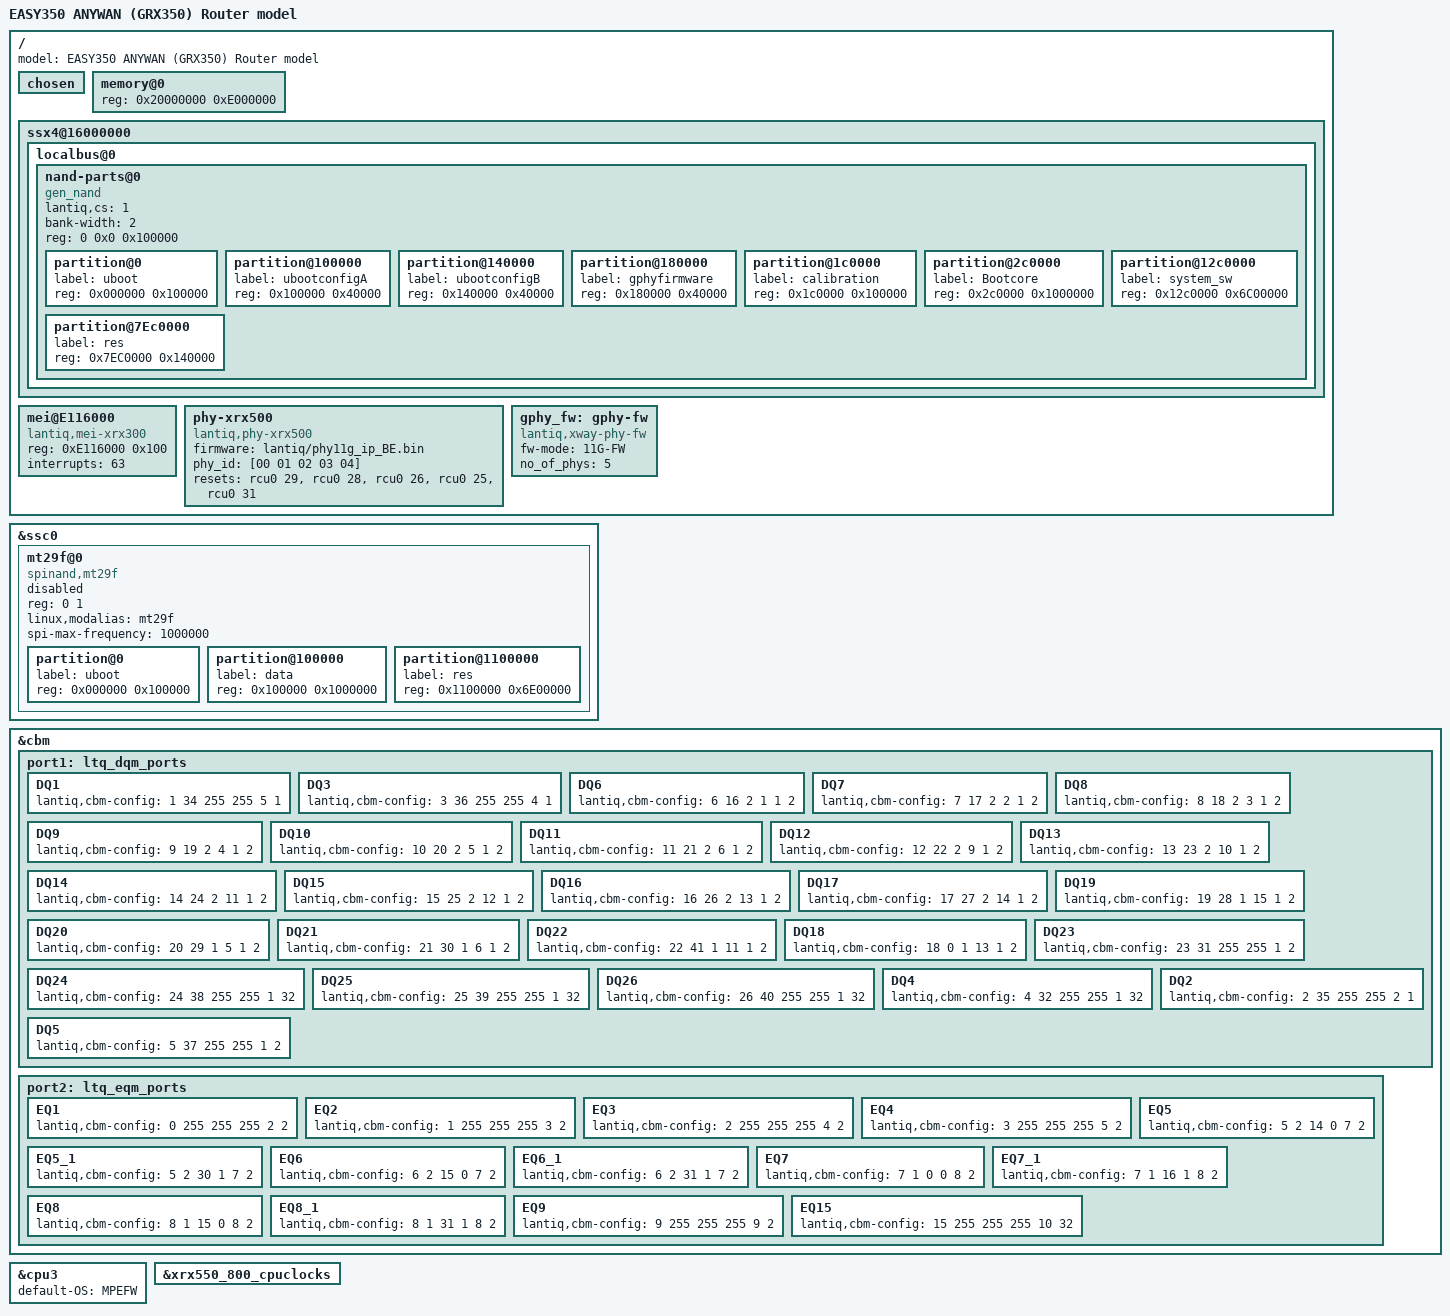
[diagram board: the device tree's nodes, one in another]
/dts-v1/;

/*****************************************************************
** Include a chip configuration file                             
*****************************************************************/
/include/ "xrx500.dtsi"
/*****************************************************************
** Include a board configuration file                             
*****************************************************************/
/include/ "xrx500_anywan_bc.dtsi"

/ {

	model = "EASY350 ANYWAN (GRX350) Router model";

	chosen {
		//bootargs-append = "maxcpus=4 cca=5 pci=pcie_bus_perf";
        };

	memory@0 {
		device_type = "memory";
		reg = <0x20000000 0xE000000>;
	};

	ssx4@16000000 {
			localbus@0 {
			ranges = <0 0 0x1c00000 0xfffff>;
			nand-parts@0 {
				compatible = "gen_nand","lantiq,nand-xway";
				lantiq,cs = <1>;
				bank-width = <2>;
				reg = <0 0x0 0x100000>;
				#address-cells = <1>;
				#size-cells = <1>;

                                partition@0 {
                                        label = "uboot";
                                        reg = <0x000000 0x100000>;
                                };

                                partition@100000 {
                                        label = "ubootconfigA";
                                        reg = <0x100000 0x40000>;
                                };

                                partition@140000 {
                                        label = "ubootconfigB";
                                        reg = <0x140000 0x40000>;
                                };

                                partition@180000 {
                                        label = "gphyfirmware";
                                        reg = <0x180000 0x40000>;
                                };

                                partition@1c0000 {
                                        label = "calibration";
                                        reg = <0x1c0000 0x100000>;
                                };

                               partition@2c0000 {
                                        label = "Bootcore";
                                        reg = <0x2c0000 0x1000000>;
                                };

                                partition@12c0000 {
                                        label = "system_sw";
                                        reg = <0x12c0000 0x6C00000>;
                                };

                                partition@7Ec0000 {
                                        label = "res";
                                        reg = <0x7EC0000 0x140000>;
                                };
			};
		};
	};
};

/******************************************************************************
** Model configuration: Enable SSC0 to support standard SPI devices (SPI Flash)  
******************************************************************************/
&ssc0 {
		
		mt29f@0 {
				status="disabled";
				#address-cells = <1>;
				#size-cells = <1>;
				reg = <0 1>;
				compatible = "spinand,mt29f";
				linux,modalias = "mt29f";
				spi-max-frequency = <1000000>;

				partition@0 {
					label = "uboot";
					reg = <0x000000 0x100000>;
				};

				partition@100000 {
					label = "data";
					reg = <0x100000 0x1000000>;
				};	
				
				partition@1100000 {
					label = "res";
					reg = <0x1100000 0x6E00000>;
				};
			};
};

/ {
/******************************************************************************
** Board configuration: MEI setting might not be needed for VRX318
******************************************************************************/
        mei@E116000 {
		            compatible = "lantiq,mei-xrx300";
					reg = <0xE116000 0x100>;
					interrupts = <63>;
	};
};

/{
/******************************************************************************
** Model configuration: Select Gigabit or fast ethernet firmware to load to 
** internel GPHY.
** GE mode : 11G-FW
** FE mode : 22F-FW
******************************************************************************/
	phy-xrx500 {
        compatible = "lantiq,phy-xrx500";
	    firmware = "lantiq/phy11g_ip_BE.bin";
		phy_id = [00 01 02 03 04];
		resets = <&rcu0 29>, <&rcu0 28>, <&rcu0 26>, <&rcu0 25>, <&rcu0 31>;
		reset-names = "phy0", "phy1", "phy2", "phy3", "phy4";
	};

	gphy_fw: gphy-fw {
		compatible = "lantiq,xway-phy-fw";
		fw-mode = "11G-FW"; /*"11G-FW"*/ /*22F-FW*/
		no_of_phys = <5>;
	};
};
/*******************************************************************************/

/******************************************************************************
** Model configuration: CBM sub-system feature configuration, the cbm node is 
** defined in Soc level. 
** <Port> <Queue> <DMA_Ctrl> <DMA_chnl> <EN/DIS/TYPE> <number of desc>
** <DIS 0> <EN 1> <TYPE DP_F_DEQ_CPU 0x2> <TYPE DP_F_DEQ_CPU1 0x3> 
** <TYPE DP_F_DEQ_MPE 0x4>
******************************************************************************/
&cbm {
			        status = "ok";
				port1: ltq_dqm_ports {
					DQ1 {
				 		lantiq,cbm-config = <1 34 255 255 5 1>;
					};
					DQ3 {
				 		lantiq,cbm-config = <3 36 255 255 4 1>;
					};
					DQ6 {
						lantiq,cbm-config = <6 16 2 1 1 2>;
					};
					DQ7 {
						lantiq,cbm-config = <7 17 2 2 1 2>;
					};
					DQ8 {
						lantiq,cbm-config = <8 18 2 3 1 2>;
					};
					DQ9 {
						lantiq,cbm-config = <9 19 2 4 1 2>;
					};
					DQ10 {
						lantiq,cbm-config = <10 20 2 5 1 2>;
					};
					DQ11 {
						lantiq,cbm-config = <11 21 2 6 1 2>;
					};
					DQ12 {
						lantiq,cbm-config = <12 22 2 9 1 2>;
					};
					DQ13 {
						lantiq,cbm-config = <13 23 2 10 1 2>;
					};
					DQ14 {
						lantiq,cbm-config = <14 24 2 11 1 2>;
					};
					DQ15 {
						lantiq,cbm-config = <15 25 2 12 1 2>;
					};
					DQ16 {
						lantiq,cbm-config = <16 26 2 13 1 2>;
					};
					DQ17 {
						lantiq,cbm-config = <17 27 2 14 1 2>;
					};
					DQ19 {
						lantiq,cbm-config = <19 28 1 15 1 2>;
					};
					DQ20 {
						lantiq,cbm-config = <20 29 1 5 1 2>;
					};
					DQ21 {
						lantiq,cbm-config = <21 30 1 6 1 2>;
					};
					DQ22 {
						lantiq,cbm-config = <22 41 1 11 1 2>;
					};
					DQ18 {
						lantiq,cbm-config = <18 0 1 13 1 2>;
					};
					DQ23 {
						lantiq,cbm-config = <23 31 255 255 1 2>;
					};
					DQ24 {
						lantiq,cbm-config = <24 38 255 255 1 32>;
					};
					DQ25 {
						lantiq,cbm-config = <25 39 255 255 1 32>;
					};
					DQ26 {
						lantiq,cbm-config = <26 40 255 255 1 32>;
					};
					DQ4 {
						lantiq,cbm-config = <4 32 255 255 1 32>;
					};
					/*DQ0 {
						lantiq,cbm-config = <0 33 255 255 3 1>;
					};*/
					DQ2 {
						lantiq,cbm-config = <2 35 255 255 2 1>;
					};
					DQ5 {
						lantiq,cbm-config = <5 37 255 255 1 2>;
					};
				};
				/*<Port> <Queue> <DMA_Ctrl> <DMA_chnl> <EN/DIS/TYPE> <number of desc>*/
				/*<DIS 0>
				<EN 1>
				<TYPE DP_F_ENQ_CPU_0 0x2>
				<TYPE DP_F_ENQ_CPU_1 0x3>
				<TYPE DP_F_ENQ_CPU_2 0x4>
				<TYPE DP_F_ENQ_CPU_3 0x5>
				<TYPE DP_F_ENQ_WAVE  0x6>
				<TYPE DP_F_ENQ_GSWIPL 0x7>
				<TYPE DP_F_ENQ_PAE 0x8>
				<TYPE DP_F_ENQ_TSO 0x9>
				<TYPE DP_F_ENQ_VRX318 0xa>*/
					port2: ltq_eqm_ports {
					EQ1 {
						lantiq,cbm-config = <0 255 255 255 2 2>;
					};
					EQ2 {
						lantiq,cbm-config = <1 255 255 255 3 2>;
					};
					EQ3 {
						lantiq,cbm-config = <2 255 255 255 4 2>;
					};
					EQ4 {
						lantiq,cbm-config = <3 255 255 255 5 2>;
					};
					EQ5 {
						lantiq,cbm-config = <5 2 14 0 7 2>;
					};
					EQ5_1 {
						lantiq,cbm-config = <5 2 30 1 7 2>;
					};
					EQ6 {
						lantiq,cbm-config = <6 2 15 0 7 2>;
					};
					EQ6_1 {
						lantiq,cbm-config = <6 2 31 1 7 2>;
					};
					EQ7 {
						lantiq,cbm-config = <7 1 0 0 8 2>;
					};
					EQ7_1 {
						lantiq,cbm-config = <7 1 16 1 8 2>;
					};
					EQ8 {
						lantiq,cbm-config = <8 1 15 0 8 2>;
					};
					EQ8_1 {
						lantiq,cbm-config = <8 1 31 1 8 2>;
					};
					EQ9 {
						lantiq,cbm-config = <9 255 255 255 9 2>;
					};
					EQ15 {
						lantiq,cbm-config = <15 255 255 255 10 32>;
					};
			};
};
/******************************************************************************/

/******************************************************************************
** Model configuration: Arrange specific FW to run on VPEs. 
******************************************************************************/
/* use CPU3 for MPE firmware */
&cpu3 {
	default-OS = "MPEFW";
};

/******************************************************************************/

/******************************************************************************
** Model configuration: CPU Clock Setting for this model. 
******************************************************************************/
/* configure cpu clock to 800 MHz*/
&xrx550_800_cpuclocks {	
	status = "okay";
};

/******************************************************************************/
